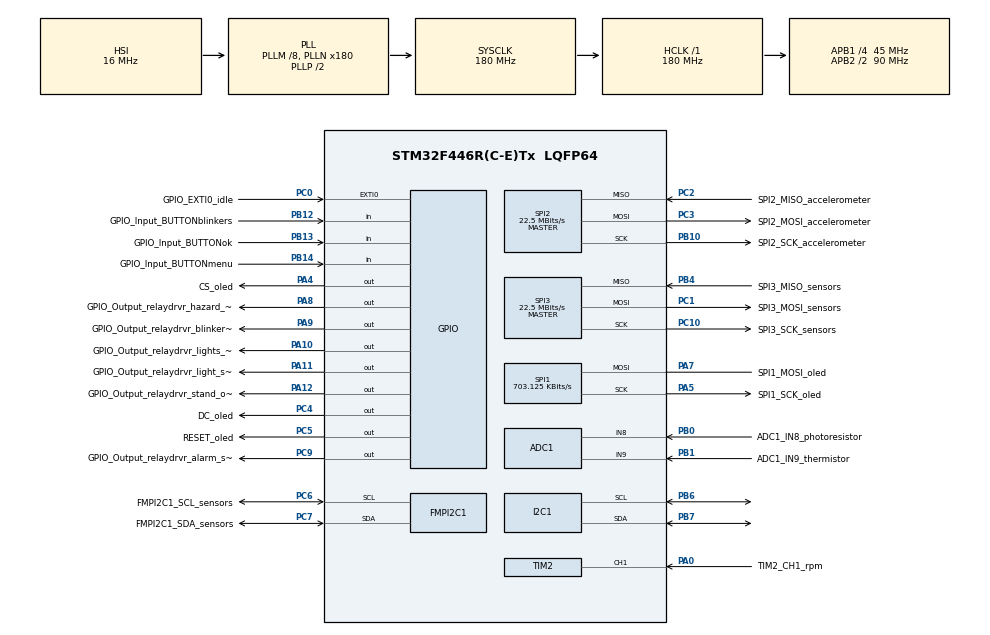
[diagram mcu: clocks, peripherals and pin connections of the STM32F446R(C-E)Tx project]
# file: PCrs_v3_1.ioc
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ADC1.Channel-0\#ChannelRegularConversion=ADC_CHANNEL_8
ADC1.ContinuousConvMode=ENABLE
ADC1.NbrOfConversionFlag=1
ADC1.Rank-0\#ChannelRegularConversion=1
ADC1.SamplingTime-0\#ChannelRegularConversion=ADC_SAMPLETIME_3CYCLES
ADC1.master=1
FMPI2C1.FMPI2C_Speed_Mode=FMPI2C_Fast_Plus
FMPI2C1.Timing=0x0020081B
Mcu.Family=STM32F4
Mcu.Name=STM32F446R(C-E)Tx
Mcu.Package=LQFP64
NVIC.EXTI0_IRQn=true\:0\:0\:false\:false\:true\:true\:true\:true
NVIC.PriorityGroup=NVIC_PRIORITYGROUP_4
NVIC.TIM1_UP_TIM10_IRQn=true\:0\:0\:false\:false\:true\:true\:true\:true
NVIC.TIM2_IRQn=true\:0\:0\:false\:false\:true\:true\:true\:true
PA0-WKUP.GPIO_Label=TIM2_CH1_rpm
PA0-WKUP.Signal=S_TIM2_CH1_ETR
PA10.GPIO_Label=GPIO_Output_relaydrvr_lights_mode
PA10.Signal=GPIO_Output
PA11.GPIO_Label=GPIO_Output_relaydrvr_light_sel
PA11.Signal=GPIO_Output
PA12.GPIO_Label=GPIO_Output_relaydrvr_stand_onoff
PA12.Signal=GPIO_Output
PA13.Signal=SYS_JTMS-SWDIO
PA14.Signal=SYS_JTCK-SWCLK
PA4.GPIO_Label=CS_oled
PA4.Signal=GPIO_Output
PA5.GPIO_Label=SPI1_SCK_oled
PA5.Mode=Simplex_Bidirectional_Master
PA5.Signal=SPI1_SCK
PA7.GPIO_Label=SPI1_MOSI_oled
PA7.Mode=Simplex_Bidirectional_Master
PA7.Signal=SPI1_MOSI
PA8.GPIO_Label=GPIO_Output_relaydrvr_hazard_lights
PA8.Signal=GPIO_Output
PA9.GPIO_Label=GPIO_Output_relaydrvr_blinkers_together
PA9.Signal=GPIO_Output
PB0.GPIO_Label=ADC1_IN8_photoresistor
PB0.Signal=ADCx_IN8
PB1.GPIO_Label=ADC1_IN9_thermistor
PB1.Signal=ADCx_IN9
PB10.GPIO_Label=SPI2_SCK_accelerometer
PB10.Mode=Full_Duplex_Master
PB10.Signal=SPI2_SCK
PB12.GPIO_Label=GPIO_Input_BUTTONblinkers
PB12.GPIO_PuPd=GPIO_PULLUP
PB12.Signal=GPIO_Input
PB13.GPIO_Label=GPIO_Input_BUTTONok
PB13.GPIO_PuPd=GPIO_PULLUP
PB13.Signal=GPIO_Input
PB14.GPIO_Label=GPIO_Input_BUTTONmenu
PB14.GPIO_PuPd=GPIO_PULLUP
PB14.Signal=GPIO_Input
PB4.GPIO_Label=SPI3_MISO_sensors
PB4.Mode=Full_Duplex_Master
PB4.Signal=SPI3_MISO
PB6.Mode=I2C
PB6.Signal=I2C1_SCL
PB7.Mode=I2C
PB7.Signal=I2C1_SDA
PC0.GPIO_Label=GPIO_EXTI0_idle
PC0.GPIO_ModeDefaultEXTI=GPIO_MODE_IT_RISING_FALLING
PC0.GPIO_PuPd=GPIO_PULLUP
PC0.Signal=GPXTI0
PC1.GPIO_Label=SPI3_MOSI_sensors
PC1.Mode=Full_Duplex_Master
PC1.Signal=SPI3_MOSI
PC10.GPIO_Label=SPI3_SCK_sensors
PC10.Mode=Full_Duplex_Master
PC10.Signal=SPI3_SCK
PC2.GPIO_Label=SPI2_MISO_accelerometer
PC2.Mode=Full_Duplex_Master
PC2.Signal=SPI2_MISO
PC3.GPIO_Label=SPI2_MOSI_accelerometer
PC3.Mode=Full_Duplex_Master
PC3.Signal=SPI2_MOSI
PC4.GPIO_Label=DC_oled
PC4.Signal=GPIO_Output
PC5.GPIO_Label=RESET_oled
PC5.Signal=GPIO_Output
PC6.GPIO_Label=FMPI2C1_SCL_sensors
PC6.Mode=I2C
PC6.Signal=FMPI2C1_SCL
PC7.GPIO_Label=FMPI2C1_SDA_sensors
PC7.Mode=I2C
PC7.Signal=FMPI2C1_SDA
PC9.GPIO_Label=GPIO_Output_relaydrvr_alarm_siren
PC9.Signal=GPIO_Output
ProjectManager.HeapSize=0x200
ProjectManager.StackSize=0x400
ProjectManager.TargetToolchain=STM32CubeIDE
RCC.AHBFreq_Value=180000000
RCC.APB1CLKDivider=RCC_HCLK_DIV4
RCC.APB1Freq_Value=45000000
RCC.APB1TimFreq_Value=90000000
RCC.APB2CLKDivider=RCC_HCLK_DIV2
RCC.APB2Freq_Value=90000000
RCC.APB2TimFreq_Value=180000000
RCC.CortexFreq_Value=180000000
RCC.HCLKFreq_Value=180000000
RCC.PLLM=8
RCC.PLLN=180
RCC.PLLQ=8
RCC.SYSCLKFreq_VALUE=180000000
RCC.SYSCLKSource=RCC_SYSCLKSOURCE_PLLCLK
RCC.USBFreq_Value=45000000
RCC.VCOOutputFreq_Value=360000000
RTC.Date=1
RTC.Hours=0
RTC.Minutes=0
RTC.Month=RTC_MONTH_JANUARY
RTC.WeekDay=RTC_WEEKDAY_WEDNESDAY
RTC.Year=25
SH.ADCx_IN8.0=ADC1_IN8,IN8
SH.ADCx_IN9.0=ADC1_IN9,IN9
SH.S_TIM2_CH1_ETR.0=TIM2_CH1,Input_Capture1_from_TI1
SPI1.BaudRatePrescaler=SPI_BAUDRATEPRESCALER_128
SPI1.CalculateBaudRate=703.125 KBits/s
SPI1.Direction=SPI_DIRECTION_1LINE
SPI1.Mode=SPI_MODE_MASTER
SPI1.VirtualType=VM_MASTER
SPI2.CalculateBaudRate=22.5 MBits/s
SPI2.Direction=SPI_DIRECTION_2LINES
SPI2.Mode=SPI_MODE_MASTER
SPI2.VirtualType=VM_MASTER
SPI3.CalculateBaudRate=22.5 MBits/s
SPI3.Direction=SPI_DIRECTION_2LINES
SPI3.Mode=SPI_MODE_MASTER
SPI3.VirtualType=VM_MASTER
TIM1.Period=4999
TIM1.Prescaler=17999
TIM2.Channel-Input_Capture1_from_TI1=TIM_CHANNEL_1
TIM2.Prescaler=89
VP_RTC_VS_RTC_Activate.Mode=RTC_Enabled
VP_RTC_VS_RTC_Calendar.Mode=RTC_Calendar
VP_TIM1_VS_ClockSourceINT.Mode=Internal
VP_TIM2_VS_ClockSourceINT.Mode=Internal
board=custom

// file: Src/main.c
/* USER CODE BEGIN Header */
/**
  ******************************************************************************
  * @file           : main.c
  * @brief          : Main program body
  ******************************************************************************
  * @attention
  *
  * Copyright (c) 2025 STMicroelectronics.
  * All rights reserved.
  *
  * This software is licensed under terms that can be found in the LICENSE file
  * in the root directory of this software component.
  * If no LICENSE file comes with this software, it is provided AS-IS.
  *
  ******************************************************************************
  */
/* USER CODE END Header */
#include "main.h"

/* USER CODE BEGIN Includes */
#include "ssd1306.h"
/* USER CODE END Includes */

ADC_HandleTypeDef hadc1;

FMPI2C_HandleTypeDef hfmpi2c1;

I2C_HandleTypeDef hi2c1;

RTC_HandleTypeDef hrtc;

SPI_HandleTypeDef hspi1;
SPI_HandleTypeDef hspi2;
SPI_HandleTypeDef hspi3;

TIM_HandleTypeDef htim1;
TIM_HandleTypeDef htim2;

void SystemClock_Config(void);
static void MX_GPIO_Init(void);
static void MX_ADC1_Init(void);
static void MX_FMPI2C1_Init(void);
static void MX_RTC_Init(void);
static void MX_SPI1_Init(void);
static void MX_SPI2_Init(void);
static void MX_SPI3_Init(void);
static void MX_TIM2_Init(void);
static void MX_I2C1_Init(void);
static void MX_TIM1_Init(void);
/* USER CODE BEGIN PFP */
void tasker(void);
void displayer(void);
/* USER CODE END PFP */

int main(void)
{

  /* MCU Configuration--------------------------------------------------------*/

  /* Reset of all peripherals, Initializes the Flash interface and the Systick. */
  HAL_Init();

  /* Configure the system clock */
  SystemClock_Config();

  /* Initialize all configured peripherals */
  MX_GPIO_Init();
  MX_ADC1_Init();
  MX_FMPI2C1_Init();
  MX_RTC_Init();
  MX_SPI1_Init();
  MX_SPI2_Init();
  MX_SPI3_Init();
  MX_TIM2_Init();
  MX_I2C1_Init();
  MX_TIM1_Init();
  /* USER CODE BEGIN 2 */
  ssd1306_Init();
  clock_init();

  //HAL_TIM_Base_Start_IT(&htim1);	//start timer1 interrupts - always on for hazard lights

  //HAL_GPIO_WritePin(GPIO_Output_relaydrvr_lights_mode_GPIO_Port, GPIO_Output_relaydrvr_lights_mode_Pin,1);
  //relay_test(FULL);
  photo_sensor_test();
	//HAL_GPIO_WritePin(GPIO_Output_relaydrvr_alarm_siren_GPIO_Port, GPIO_Output_relaydrvr_alarm_siren_Pin,1);

	//HAL_GPIO_WritePin(GPIOx, GPIO_Pin, PinState)
  /* USER CODE END 2 */

  /* Infinite loop */
  /* USER CODE BEGIN WHILE */
  while (1)
  {

//	  displayer();
//	  tasker();
	  //HAL_Delay(10);	// TODO to simulate

    /* USER CODE END WHILE */

  }
}

void SystemClock_Config(void)
{
  RCC_OscInitTypeDef RCC_OscInitStruct = {0};
  RCC_ClkInitTypeDef RCC_ClkInitStruct = {0};

  /** Configure the main internal regulator output voltage
  */
  __HAL_RCC_PWR_CLK_ENABLE();
  __HAL_PWR_VOLTAGESCALING_CONFIG(PWR_REGULATOR_VOLTAGE_SCALE1);

  /** Initializes the RCC Oscillators according to the specified parameters
  * in the RCC_OscInitTypeDef structure.
  */
  RCC_OscInitStruct.OscillatorType = RCC_OSCILLATORTYPE_HSI|RCC_OSCILLATORTYPE_LSI;
  RCC_OscInitStruct.LSEState = RCC_LSE_OFF;
  RCC_OscInitStruct.HSIState = RCC_HSI_ON;
  RCC_OscInitStruct.HSICalibrationValue = RCC_HSICALIBRATION_DEFAULT;
  RCC_OscInitStruct.LSIState = RCC_LSI_ON;
  RCC_OscInitStruct.PLL.PLLState = RCC_PLL_ON;
  RCC_OscInitStruct.PLL.PLLSource = RCC_PLLSOURCE_HSI;
  RCC_OscInitStruct.PLL.PLLM = 8;
  RCC_OscInitStruct.PLL.PLLN = 180;
  RCC_OscInitStruct.PLL.PLLP = RCC_PLLP_DIV2;
  RCC_OscInitStruct.PLL.PLLQ = 8;
  RCC_OscInitStruct.PLL.PLLR = 2;
  if (HAL_RCC_OscConfig(&RCC_OscInitStruct) != HAL_OK)
  {
    Error_Handler();
  }

  /** Activate the Over-Drive mode
  */
  if (HAL_PWREx_EnableOverDrive() != HAL_OK)
  {
    Error_Handler();
  }

  /** Initializes the CPU, AHB and APB buses clocks
  */
  RCC_ClkInitStruct.ClockType = RCC_CLOCKTYPE_HCLK|RCC_CLOCKTYPE_SYSCLK
                              |RCC_CLOCKTYPE_PCLK1|RCC_CLOCKTYPE_PCLK2;
  RCC_ClkInitStruct.SYSCLKSource = RCC_SYSCLKSOURCE_PLLCLK;
  RCC_ClkInitStruct.AHBCLKDivider = RCC_SYSCLK_DIV1;
  RCC_ClkInitStruct.APB1CLKDivider = RCC_HCLK_DIV4;
  RCC_ClkInitStruct.APB2CLKDivider = RCC_HCLK_DIV2;

  if (HAL_RCC_ClockConfig(&RCC_ClkInitStruct, FLASH_LATENCY_5) != HAL_OK)
  {
    Error_Handler();
  }
}

static void MX_ADC1_Init(void)
{

  ADC_ChannelConfTypeDef sConfig = {0};

  /** Configure the global features of the ADC (Clock, Resolution, Data Alignment and number of conversion)
  */
  hadc1.Instance = ADC1;
  hadc1.Init.ClockPrescaler = ADC_CLOCK_SYNC_PCLK_DIV4;
  hadc1.Init.Resolution = ADC_RESOLUTION_12B;
  hadc1.Init.ScanConvMode = DISABLE;
  hadc1.Init.ContinuousConvMode = ENABLE;
  hadc1.Init.DiscontinuousConvMode = DISABLE;
  hadc1.Init.ExternalTrigConvEdge = ADC_EXTERNALTRIGCONVEDGE_NONE;
  hadc1.Init.ExternalTrigConv = ADC_SOFTWARE_START;
  hadc1.Init.DataAlign = ADC_DATAALIGN_RIGHT;
  hadc1.Init.NbrOfConversion = 1;
  hadc1.Init.DMAContinuousRequests = DISABLE;
  hadc1.Init.EOCSelection = ADC_EOC_SINGLE_CONV;
  if (HAL_ADC_Init(&hadc1) != HAL_OK)
  {
    Error_Handler();
  }

  /** Configure for the selected ADC regular channel its corresponding rank in the sequencer and its sample time.
  */
  sConfig.Channel = ADC_CHANNEL_8;
  sConfig.Rank = 1;
  sConfig.SamplingTime = ADC_SAMPLETIME_3CYCLES;
  if (HAL_ADC_ConfigChannel(&hadc1, &sConfig) != HAL_OK)
  {
    Error_Handler();
  }

}

static void MX_FMPI2C1_Init(void)
{

  hfmpi2c1.Instance = FMPI2C1;
  hfmpi2c1.Init.Timing = 0x0020081B;
  hfmpi2c1.Init.OwnAddress1 = 0;
  hfmpi2c1.Init.AddressingMode = FMPI2C_ADDRESSINGMODE_7BIT;
  hfmpi2c1.Init.DualAddressMode = FMPI2C_DUALADDRESS_DISABLE;
  hfmpi2c1.Init.OwnAddress2 = 0;
  hfmpi2c1.Init.OwnAddress2Masks = FMPI2C_OA2_NOMASK;
  hfmpi2c1.Init.GeneralCallMode = FMPI2C_GENERALCALL_DISABLE;
  hfmpi2c1.Init.NoStretchMode = FMPI2C_NOSTRETCH_DISABLE;
  if (HAL_FMPI2C_Init(&hfmpi2c1) != HAL_OK)
  {
    Error_Handler();
  }

  /** Configure Analogue filter
  */
  if (HAL_FMPI2CEx_ConfigAnalogFilter(&hfmpi2c1, FMPI2C_ANALOGFILTER_ENABLE) != HAL_OK)
  {
    Error_Handler();
  }

  /** I2C Fast mode Plus enable
  */
  HAL_FMPI2CEx_EnableFastModePlus(FMPI2C_FASTMODEPLUS_SCL);
  HAL_FMPI2CEx_EnableFastModePlus(FMPI2C_FASTMODEPLUS_SDA);

}

static void MX_I2C1_Init(void)
{

  hi2c1.Instance = I2C1;
  hi2c1.Init.ClockSpeed = 100000;
  hi2c1.Init.DutyCycle = I2C_DUTYCYCLE_2;
  hi2c1.Init.OwnAddress1 = 0;
  hi2c1.Init.AddressingMode = I2C_ADDRESSINGMODE_7BIT;
  hi2c1.Init.DualAddressMode = I2C_DUALADDRESS_DISABLE;
  hi2c1.Init.OwnAddress2 = 0;
  hi2c1.Init.GeneralCallMode = I2C_GENERALCALL_DISABLE;
  hi2c1.Init.NoStretchMode = I2C_NOSTRETCH_DISABLE;
  if (HAL_I2C_Init(&hi2c1) != HAL_OK)
  {
    Error_Handler();
  }

}

static void MX_RTC_Init(void)
{

  RTC_TimeTypeDef sTime = {0};
  RTC_DateTypeDef sDate = {0};

  /** Initialize RTC Only
  */
  hrtc.Instance = RTC;
  hrtc.Init.HourFormat = RTC_HOURFORMAT_24;
  hrtc.Init.AsynchPrediv = 127;
  hrtc.Init.SynchPrediv = 255;
  hrtc.Init.OutPut = RTC_OUTPUT_DISABLE;
  hrtc.Init.OutPutPolarity = RTC_OUTPUT_POLARITY_HIGH;
  hrtc.Init.OutPutType = RTC_OUTPUT_TYPE_OPENDRAIN;
  if (HAL_RTC_Init(&hrtc) != HAL_OK)
  {
    Error_Handler();
  }

  /** Initialize RTC and set the Time and Date
  */
  sTime.Hours = 0x0;
  sTime.Minutes = 0x0;
  sTime.Seconds = 0x0;
  sTime.DayLightSaving = RTC_DAYLIGHTSAVING_NONE;
  sTime.StoreOperation = RTC_STOREOPERATION_RESET;
  if (HAL_RTC_SetTime(&hrtc, &sTime, RTC_FORMAT_BCD) != HAL_OK)
  {
    Error_Handler();
  }
  sDate.WeekDay = RTC_WEEKDAY_WEDNESDAY;
  sDate.Month = RTC_MONTH_JANUARY;
  sDate.Date = 0x1;
  sDate.Year = 0x25;

  if (HAL_RTC_SetDate(&hrtc, &sDate, RTC_FORMAT_BCD) != HAL_OK)
  {
    Error_Handler();
  }

}

static void MX_SPI1_Init(void)
{

  /* SPI1 parameter configuration*/
  hspi1.Instance = SPI1;
  hspi1.Init.Mode = SPI_MODE_MASTER;
  hspi1.Init.Direction = SPI_DIRECTION_1LINE;
  hspi1.Init.DataSize = SPI_DATASIZE_8BIT;
  hspi1.Init.CLKPolarity = SPI_POLARITY_LOW;
  hspi1.Init.CLKPhase = SPI_PHASE_1EDGE;
  hspi1.Init.NSS = SPI_NSS_SOFT;
  hspi1.Init.BaudRatePrescaler = SPI_BAUDRATEPRESCALER_128;
  hspi1.Init.FirstBit = SPI_FIRSTBIT_MSB;
  hspi1.Init.TIMode = SPI_TIMODE_DISABLE;
  hspi1.Init.CRCCalculation = SPI_CRCCALCULATION_DISABLE;
  hspi1.Init.CRCPolynomial = 10;
  if (HAL_SPI_Init(&hspi1) != HAL_OK)
  {
    Error_Handler();
  }

}

static void MX_SPI2_Init(void)
{

  /* SPI2 parameter configuration*/
  hspi2.Instance = SPI2;
  hspi2.Init.Mode = SPI_MODE_MASTER;
  hspi2.Init.Direction = SPI_DIRECTION_2LINES;
  hspi2.Init.DataSize = SPI_DATASIZE_8BIT;
  hspi2.Init.CLKPolarity = SPI_POLARITY_LOW;
  hspi2.Init.CLKPhase = SPI_PHASE_1EDGE;
  hspi2.Init.NSS = SPI_NSS_SOFT;
  hspi2.Init.BaudRatePrescaler = SPI_BAUDRATEPRESCALER_2;
  hspi2.Init.FirstBit = SPI_FIRSTBIT_MSB;
  hspi2.Init.TIMode = SPI_TIMODE_DISABLE;
  hspi2.Init.CRCCalculation = SPI_CRCCALCULATION_DISABLE;
  hspi2.Init.CRCPolynomial = 10;
  if (HAL_SPI_Init(&hspi2) != HAL_OK)
  {
    Error_Handler();
  }

}

static void MX_SPI3_Init(void)
{

  /* SPI3 parameter configuration*/
  hspi3.Instance = SPI3;
  hspi3.Init.Mode = SPI_MODE_MASTER;
  hspi3.Init.Direction = SPI_DIRECTION_2LINES;
  hspi3.Init.DataSize = SPI_DATASIZE_8BIT;
  hspi3.Init.CLKPolarity = SPI_POLARITY_LOW;
  hspi3.Init.CLKPhase = SPI_PHASE_1EDGE;
  hspi3.Init.NSS = SPI_NSS_SOFT;
  hspi3.Init.BaudRatePrescaler = SPI_BAUDRATEPRESCALER_2;
  hspi3.Init.FirstBit = SPI_FIRSTBIT_MSB;
  hspi3.Init.TIMode = SPI_TIMODE_DISABLE;
  hspi3.Init.CRCCalculation = SPI_CRCCALCULATION_DISABLE;
  hspi3.Init.CRCPolynomial = 10;
  if (HAL_SPI_Init(&hspi3) != HAL_OK)
  {
    Error_Handler();
  }

}

static void MX_TIM1_Init(void)
{

  TIM_ClockConfigTypeDef sClockSourceConfig = {0};
  TIM_MasterConfigTypeDef sMasterConfig = {0};

  htim1.Instance = TIM1;
  htim1.Init.Prescaler = 17999;
  htim1.Init.CounterMode = TIM_COUNTERMODE_UP;
  htim1.Init.Period = 4999;
  htim1.Init.ClockDivision = TIM_CLOCKDIVISION_DIV1;
  htim1.Init.RepetitionCounter = 0;
  htim1.Init.AutoReloadPreload = TIM_AUTORELOAD_PRELOAD_DISABLE;
  if (HAL_TIM_Base_Init(&htim1) != HAL_OK)
  {
    Error_Handler();
  }
  sClockSourceConfig.ClockSource = TIM_CLOCKSOURCE_INTERNAL;
  if (HAL_TIM_ConfigClockSource(&htim1, &sClockSourceConfig) != HAL_OK)
  {
    Error_Handler();
  }
  sMasterConfig.MasterOutputTrigger = TIM_TRGO_RESET;
  sMasterConfig.MasterSlaveMode = TIM_MASTERSLAVEMODE_DISABLE;
  if (HAL_TIMEx_MasterConfigSynchronization(&htim1, &sMasterConfig) != HAL_OK)
  {
    Error_Handler();
  }

}

static void MX_TIM2_Init(void)
{

  TIM_ClockConfigTypeDef sClockSourceConfig = {0};
  TIM_MasterConfigTypeDef sMasterConfig = {0};
  TIM_IC_InitTypeDef sConfigIC = {0};

  htim2.Instance = TIM2;
  htim2.Init.Prescaler = 89;
  htim2.Init.CounterMode = TIM_COUNTERMODE_UP;
  htim2.Init.Period = 4294967295;
  htim2.Init.ClockDivision = TIM_CLOCKDIVISION_DIV1;
  htim2.Init.AutoReloadPreload = TIM_AUTORELOAD_PRELOAD_DISABLE;
  if (HAL_TIM_Base_Init(&htim2) != HAL_OK)
  {
    Error_Handler();
  }
  sClockSourceConfig.ClockSource = TIM_CLOCKSOURCE_INTERNAL;
  if (HAL_TIM_ConfigClockSource(&htim2, &sClockSourceConfig) != HAL_OK)
  {
    Error_Handler();
  }
  if (HAL_TIM_IC_Init(&htim2) != HAL_OK)
  {
    Error_Handler();
  }
  sMasterConfig.MasterOutputTrigger = TIM_TRGO_RESET;
  sMasterConfig.MasterSlaveMode = TIM_MASTERSLAVEMODE_DISABLE;
  if (HAL_TIMEx_MasterConfigSynchronization(&htim2, &sMasterConfig) != HAL_OK)
  {
    Error_Handler();
  }
  sConfigIC.ICPolarity = TIM_INPUTCHANNELPOLARITY_RISING;
  sConfigIC.ICSelection = TIM_ICSELECTION_DIRECTTI;
  sConfigIC.ICPrescaler = TIM_ICPSC_DIV1;
  sConfigIC.ICFilter = 0;
  if (HAL_TIM_IC_ConfigChannel(&htim2, &sConfigIC, TIM_CHANNEL_1) != HAL_OK)
  {
    Error_Handler();
  }

}

static void MX_GPIO_Init(void)
{
  GPIO_InitTypeDef GPIO_InitStruct = {0};

  /* GPIO Ports Clock Enable */
  __HAL_RCC_GPIOC_CLK_ENABLE();
  __HAL_RCC_GPIOA_CLK_ENABLE();
  __HAL_RCC_GPIOB_CLK_ENABLE();

  /*Configure GPIO pin Output Level */
  HAL_GPIO_WritePin(GPIOA, CS_oled_Pin|GPIO_Output_relaydrvr_hazard_lights_Pin|GPIO_Output_relaydrvr_blinkers_together_Pin|GPIO_Output_relaydrvr_lights_mode_Pin
                          |GPIO_Output_relaydrvr_light_sel_Pin|GPIO_Output_relaydrvr_stand_onoff_Pin, GPIO_PIN_RESET);

  /*Configure GPIO pin Output Level */
  HAL_GPIO_WritePin(GPIOC, DC_oled_Pin|RESET_oled_Pin|GPIO_Output_relaydrvr_alarm_siren_Pin, GPIO_PIN_RESET);

  /*Configure GPIO pin : GPIO_EXTI0_idle_Pin */
  GPIO_InitStruct.Pin = GPIO_EXTI0_idle_Pin;
  GPIO_InitStruct.Mode = GPIO_MODE_IT_RISING_FALLING;
  GPIO_InitStruct.Pull = GPIO_PULLUP;
  HAL_GPIO_Init(GPIO_EXTI0_idle_GPIO_Port, &GPIO_InitStruct);

  /*Configure GPIO pins : CS_oled_Pin GPIO_Output_relaydrvr_hazard_lights_Pin GPIO_Output_relaydrvr_blinkers_together_Pin GPIO_Output_relaydrvr_lights_mode_Pin
                           GPIO_Output_relaydrvr_light_sel_Pin GPIO_Output_relaydrvr_stand_onoff_Pin */
  GPIO_InitStruct.Pin = CS_oled_Pin|GPIO_Output_relaydrvr_hazard_lights_Pin|GPIO_Output_relaydrvr_blinkers_together_Pin|GPIO_Output_relaydrvr_lights_mode_Pin
                          |GPIO_Output_relaydrvr_light_sel_Pin|GPIO_Output_relaydrvr_stand_onoff_Pin;
  GPIO_InitStruct.Mode = GPIO_MODE_OUTPUT_PP;
  GPIO_InitStruct.Pull = GPIO_NOPULL;
  GPIO_InitStruct.Speed = GPIO_SPEED_FREQ_LOW;
  HAL_GPIO_Init(GPIOA, &GPIO_InitStruct);

  /*Configure GPIO pins : DC_oled_Pin RESET_oled_Pin GPIO_Output_relaydrvr_alarm_siren_Pin */
  GPIO_InitStruct.Pin = DC_oled_Pin|RESET_oled_Pin|GPIO_Output_relaydrvr_alarm_siren_Pin;
  GPIO_InitStruct.Mode = GPIO_MODE_OUTPUT_PP;
  GPIO_InitStruct.Pull = GPIO_NOPULL;
  GPIO_InitStruct.Speed = GPIO_SPEED_FREQ_LOW;
  HAL_GPIO_Init(GPIOC, &GPIO_InitStruct);

  /*Configure GPIO pins : GPIO_Input_BUTTONblinkers_Pin GPIO_Input_BUTTONok_Pin GPIO_Input_BUTTONmenu_Pin */
  GPIO_InitStruct.Pin = GPIO_Input_BUTTONblinkers_Pin|GPIO_Input_BUTTONok_Pin|GPIO_Input_BUTTONmenu_Pin;
  GPIO_InitStruct.Mode = GPIO_MODE_INPUT;
  GPIO_InitStruct.Pull = GPIO_PULLUP;
  HAL_GPIO_Init(GPIOB, &GPIO_InitStruct);

  /* EXTI interrupt init*/
  HAL_NVIC_SetPriority(EXTI0_IRQn, 0, 0);
  HAL_NVIC_EnableIRQ(EXTI0_IRQn);

}

void Error_Handler(void)
{
  __disable_irq();
  while (1)
  {
  }
}
